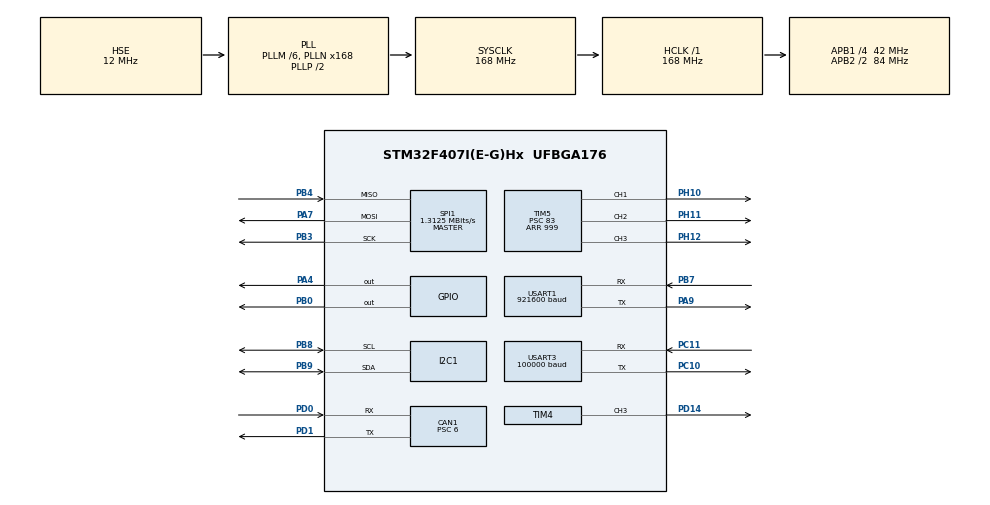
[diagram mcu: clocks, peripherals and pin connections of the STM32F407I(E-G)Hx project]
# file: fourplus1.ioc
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CAN1.BS1=CAN_BS1_3TQ
CAN1.BS2=CAN_BS2_3TQ
CAN1.CalculateBaudRate=1000000
CAN1.CalculateTimeBit=1000
CAN1.CalculateTimeQuantum=142.85714285714286
CAN1.Prescaler=6
Dma.Request0=USART3_RX
Dma.Request1=USART1_TX
Dma.USART1_TX.1.Direction=DMA_MEMORY_TO_PERIPH
Dma.USART1_TX.1.FIFOMode=DMA_FIFOMODE_DISABLE
Dma.USART1_TX.1.Instance=DMA2_Stream7
Dma.USART1_TX.1.MemDataAlignment=DMA_MDATAALIGN_BYTE
Dma.USART1_TX.1.MemInc=DMA_MINC_ENABLE
Dma.USART1_TX.1.Mode=DMA_NORMAL
Dma.USART1_TX.1.PeriphDataAlignment=DMA_PDATAALIGN_BYTE
Dma.USART1_TX.1.PeriphInc=DMA_PINC_DISABLE
Dma.USART1_TX.1.Priority=DMA_PRIORITY_LOW
Dma.USART3_RX.0.Direction=DMA_PERIPH_TO_MEMORY
Dma.USART3_RX.0.FIFOMode=DMA_FIFOMODE_DISABLE
Dma.USART3_RX.0.Instance=DMA1_Stream1
Dma.USART3_RX.0.MemDataAlignment=DMA_MDATAALIGN_BYTE
Dma.USART3_RX.0.MemInc=DMA_MINC_ENABLE
Dma.USART3_RX.0.Mode=DMA_NORMAL
Dma.USART3_RX.0.PeriphDataAlignment=DMA_PDATAALIGN_BYTE
Dma.USART3_RX.0.PeriphInc=DMA_PINC_DISABLE
Dma.USART3_RX.0.Priority=DMA_PRIORITY_LOW
FREERTOS.Tasks01=defaultTask,24,128,StartDefaultTask,Default,NULL,Dynamic,NULL,NULL;buzzer_task,8,128,StartBuzzerTask,Default,NULL,Dynamic,NULL,NULL;led_task,8,128,StartLedTask,Default,NULL,Dynamic,NULL,NULL;imu_task,40,256,StartImuTask,Default,NULL,Dynamic,NULL,NULL;rc_task,24,256,StartRcTask,Default,NULL,Dynamic,NULL,NULL;motor_task,48,256,StartMotorTask,Default,NULL,Dynamic,NULL,NULL
FREERTOS.configUSE_NEWLIB_REENTRANT=1
I2C1.I2C_Mode=I2C_Fast
Mcu.Family=STM32F4
Mcu.Name=STM32F407I(E-G)Hx
Mcu.Package=UFBGA176
NVIC.CAN1_RX0_IRQn=true\:5\:0\:false\:false\:true\:true\:true\:true\:true
NVIC.DMA1_Stream1_IRQn=true\:5\:0\:false\:false\:true\:true\:false\:true\:true
NVIC.DMA2_Stream7_IRQn=true\:5\:0\:false\:false\:true\:true\:false\:true\:true
NVIC.PriorityGroup=NVIC_PRIORITYGROUP_4
NVIC.TIM1_UP_TIM10_IRQn=true\:15\:0\:false\:false\:true\:false\:false\:true\:true
NVIC.TimeBase=TIM1_UP_TIM10_IRQn
NVIC.TimeBaseIP=TIM1
NVIC.USART3_IRQn=true\:5\:0\:false\:false\:true\:true\:true\:true\:true
PA13.Mode=Serial_Wire
PA13.Signal=SYS_JTMS-SWDIO
PA14.Mode=Serial_Wire
PA14.Signal=SYS_JTCK-SWCLK
PA4.PinState=GPIO_PIN_SET
PA4.Signal=GPIO_Output
PA7.Mode=Full_Duplex_Master
PA7.Signal=SPI1_MOSI
PA9.Mode=Asynchronous
PA9.Signal=USART1_TX
PB0.PinState=GPIO_PIN_SET
PB0.Signal=GPIO_Output
PB3.Mode=Full_Duplex_Master
PB3.Signal=SPI1_SCK
PB4.Mode=Full_Duplex_Master
PB4.Signal=SPI1_MISO
PB7.Mode=Asynchronous
PB7.Signal=USART1_RX
PB8.Mode=I2C
PB8.Signal=I2C1_SCL
PB9.Mode=I2C
PB9.Signal=I2C1_SDA
PC10.Mode=Asynchronous
PC10.Signal=USART3_TX
PC11.Mode=Asynchronous
PC11.Signal=USART3_RX
PD0.Mode=CAN_Activate
PD0.Signal=CAN1_RX
PD1.Mode=CAN_Activate
PD1.Signal=CAN1_TX
PD14.Signal=S_TIM4_CH3
PH0-OSC_IN.Mode=HSE-External-Oscillator
PH0-OSC_IN.Signal=RCC_OSC_IN
PH1-OSC_OUT.Mode=HSE-External-Oscillator
PH1-OSC_OUT.Signal=RCC_OSC_OUT
PH10.Signal=S_TIM5_CH1
PH11.Signal=S_TIM5_CH2
PH12.Signal=S_TIM5_CH3
ProjectManager.HeapSize=0x200
ProjectManager.StackSize=0x400
ProjectManager.TargetToolchain=CMake
RCC.48MHZClocksFreq_Value=84000000
RCC.AHBFreq_Value=168000000
RCC.APB1CLKDivider=RCC_HCLK_DIV4
RCC.APB1Freq_Value=42000000
RCC.APB1TimFreq_Value=84000000
RCC.APB2CLKDivider=RCC_HCLK_DIV2
RCC.APB2Freq_Value=84000000
RCC.APB2TimFreq_Value=168000000
RCC.CortexFreq_Value=168000000
RCC.HCLKFreq_Value=168000000
RCC.HSE_VALUE=12000000
RCC.HSI_VALUE=16000000
RCC.LSE_VALUE=32768
RCC.PLLM=6
RCC.PLLN=168
RCC.PLLSourceVirtual=RCC_PLLSOURCE_HSE
RCC.SYSCLKFreq_VALUE=168000000
RCC.SYSCLKSource=RCC_SYSCLKSOURCE_PLLCLK
RCC.VCOOutputFreq_Value=336000000
SH.S_TIM4_CH3.0=TIM4_CH3,PWM Generation3 CH3
SH.S_TIM5_CH1.0=TIM5_CH1,PWM Generation1 CH1
SH.S_TIM5_CH2.0=TIM5_CH2,PWM Generation2 CH2
SH.S_TIM5_CH3.0=TIM5_CH3,PWM Generation3 CH3
SPI1.BaudRatePrescaler=SPI_BAUDRATEPRESCALER_64
SPI1.CLKPhase=SPI_PHASE_2EDGE
SPI1.CLKPolarity=SPI_POLARITY_HIGH
SPI1.CalculateBaudRate=1.3125 MBits/s
SPI1.Direction=SPI_DIRECTION_2LINES
SPI1.Mode=SPI_MODE_MASTER
SPI1.VirtualType=VM_MASTER
TIM4.Channel-PWM\ Generation3\ CH3=TIM_CHANNEL_3
TIM4.Period=999
TIM4.Prescaler=83
TIM4.Pulse-PWM\ Generation3\ CH3=500
TIM5.Channel-PWM\ Generation1\ CH1=TIM_CHANNEL_1
TIM5.Channel-PWM\ Generation2\ CH2=TIM_CHANNEL_2
TIM5.Channel-PWM\ Generation3\ CH3=TIM_CHANNEL_3
TIM5.Period=999
TIM5.Prescaler=83
USART1.BaudRate=921600
USART1.VirtualMode=VM_ASYNC
USART3.BaudRate=100000
USART3.Parity=PARITY_EVEN
USART3.VirtualMode=VM_ASYNC
USART3.WordLength=WORDLENGTH_9B
VP_FREERTOS_VS_CMSIS_V2.Mode=CMSIS_V2
VP_SYS_VS_tim1.Mode=TIM1
VP_TIM4_VS_ClockSourceINT.Mode=Internal
VP_TIM5_VS_ClockSourceINT.Mode=Internal
board=custom

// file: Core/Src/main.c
/* USER CODE BEGIN Header */
/**
  ******************************************************************************
  * @file           : main.c
  * @brief          : Main program body
  ******************************************************************************
  * @attention
  *
  * Copyright (c) 2026 STMicroelectronics.
  * All rights reserved.
  *
  * This software is licensed under terms that can be found in the LICENSE file
  * in the root directory of this software component.
  * If no LICENSE file comes with this software, it is provided AS-IS.
  *
  ******************************************************************************
  */
/* USER CODE END Header */
#include "main.h"
#include "cmsis_os.h"
#include "can.h"
#include "dma.h"
#include "i2c.h"
#include "spi.h"
#include "tim.h"
#include "usart.h"
#include "gpio.h"

void SystemClock_Config(void);
void MX_FREERTOS_Init(void);

int main(void)
{

  /* MCU Configuration--------------------------------------------------------*/

  /* Reset of all peripherals, Initializes the Flash interface and the Systick. */
  HAL_Init();

  /* Configure the system clock */
  SystemClock_Config();

  /* Initialize all configured peripherals */
  MX_GPIO_Init();
  MX_DMA_Init();
  MX_USART1_UART_Init();
  MX_USART3_UART_Init();
  MX_CAN1_Init();
  MX_I2C1_Init();
  MX_SPI1_Init();
  MX_TIM4_Init();
  MX_TIM5_Init();

  /* Init scheduler */
  osKernelInitialize();  /* Call init function for freertos objects (in cmsis_os2.c) */
  MX_FREERTOS_Init();

  /* Start scheduler */
  osKernelStart();

  /* We should never get here as control is now taken by the scheduler */

  /* Infinite loop */
  while (1)
  {

  }
}

void SystemClock_Config(void)
{
  RCC_OscInitTypeDef RCC_OscInitStruct = {0};
  RCC_ClkInitTypeDef RCC_ClkInitStruct = {0};

  /** Configure the main internal regulator output voltage
  */
  __HAL_RCC_PWR_CLK_ENABLE();
  __HAL_PWR_VOLTAGESCALING_CONFIG(PWR_REGULATOR_VOLTAGE_SCALE1);

  /** Initializes the RCC Oscillators according to the specified parameters
  * in the RCC_OscInitTypeDef structure.
  */
  RCC_OscInitStruct.OscillatorType = RCC_OSCILLATORTYPE_HSE;
  RCC_OscInitStruct.HSEState = RCC_HSE_ON;
  RCC_OscInitStruct.PLL.PLLState = RCC_PLL_ON;
  RCC_OscInitStruct.PLL.PLLSource = RCC_PLLSOURCE_HSE;
  RCC_OscInitStruct.PLL.PLLM = 6;
  RCC_OscInitStruct.PLL.PLLN = 168;
  RCC_OscInitStruct.PLL.PLLP = RCC_PLLP_DIV2;
  RCC_OscInitStruct.PLL.PLLQ = 4;
  if (HAL_RCC_OscConfig(&RCC_OscInitStruct) != HAL_OK)
  {
    Error_Handler();
  }

  /** Initializes the CPU, AHB and APB buses clocks
  */
  RCC_ClkInitStruct.ClockType = RCC_CLOCKTYPE_HCLK|RCC_CLOCKTYPE_SYSCLK
                              |RCC_CLOCKTYPE_PCLK1|RCC_CLOCKTYPE_PCLK2;
  RCC_ClkInitStruct.SYSCLKSource = RCC_SYSCLKSOURCE_PLLCLK;
  RCC_ClkInitStruct.AHBCLKDivider = RCC_SYSCLK_DIV1;
  RCC_ClkInitStruct.APB1CLKDivider = RCC_HCLK_DIV4;
  RCC_ClkInitStruct.APB2CLKDivider = RCC_HCLK_DIV2;

  if (HAL_RCC_ClockConfig(&RCC_ClkInitStruct, FLASH_LATENCY_5) != HAL_OK)
  {
    Error_Handler();
  }
}

/* USER CODE BEGIN 4 */
#include <stdio.h>

int __io_putchar(int ch)
{
    HAL_UART_Transmit(&huart1, (uint8_t *)&ch, 1, 0xFFFF);
    return ch;
}
/* USER CODE END 4 */

void HAL_TIM_PeriodElapsedCallback(TIM_HandleTypeDef *htim)
{
  if (htim->Instance == TIM1)
  {
    HAL_IncTick();
  }
}

void Error_Handler(void)
{
  __disable_irq();
  while (1)
  {
  }
}

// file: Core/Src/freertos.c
/* USER CODE BEGIN Header */
/**
  ******************************************************************************
  * File Name          : freertos.c
  * Description        : Code for freertos applications
  ******************************************************************************
  * @attention
  *
  * Copyright (c) 2026 STMicroelectronics.
  * All rights reserved.
  *
  * This software is licensed under terms that can be found in the LICENSE file
  * in the root directory of this software component.
  * If no LICENSE file comes with this software, it is provided AS-IS.
  *
  ******************************************************************************
  */
/* USER CODE END Header */

#include "FreeRTOS.h"
#include "task.h"
#include "main.h"
#include "cmsis_os.h"

/* Definitions for defaultTask */
osThreadId_t defaultTaskHandle;
const osThreadAttr_t defaultTask_attributes = {
  .name = "defaultTask",
  .stack_size = 128 * 4,
  .priority = (osPriority_t) osPriorityNormal,
};
/* Definitions for buzzer_task */
osThreadId_t buzzer_taskHandle;
const osThreadAttr_t buzzer_task_attributes = {
  .name = "buzzer_task",
  .stack_size = 128 * 4,
  .priority = (osPriority_t) osPriorityLow,
};
/* Definitions for led_task */
osThreadId_t led_taskHandle;
const osThreadAttr_t led_task_attributes = {
  .name = "led_task",
  .stack_size = 128 * 4,
  .priority = (osPriority_t) osPriorityLow,
};
/* Definitions for imu_task */
osThreadId_t imu_taskHandle;
const osThreadAttr_t imu_task_attributes = {
  .name = "imu_task",
  .stack_size = 256 * 4,
  .priority = (osPriority_t) osPriorityHigh,
};
/* Definitions for rc_task */
osThreadId_t rc_taskHandle;
const osThreadAttr_t rc_task_attributes = {
  .name = "rc_task",
  .stack_size = 256 * 4,
  .priority = (osPriority_t) osPriorityNormal,
};
/* Definitions for motor_task */
osThreadId_t motor_taskHandle;
const osThreadAttr_t motor_task_attributes = {
  .name = "motor_task",
  .stack_size = 256 * 4,
  .priority = (osPriority_t) osPriorityRealtime,
};

void StartDefaultTask(void *argument);
void StartBuzzerTask(void *argument);
void StartLedTask(void *argument);
void StartImuTask(void *argument);
void StartRcTask(void *argument);
void StartMotorTask(void *argument);

void MX_FREERTOS_Init(void); /* (MISRA C 2004 rule 8.1) */

void MX_FREERTOS_Init(void) {

  /* Create the thread(s) */
  /* creation of defaultTask */
  defaultTaskHandle = osThreadNew(StartDefaultTask, NULL, &defaultTask_attributes);

  /* creation of buzzer_task */
  buzzer_taskHandle = osThreadNew(StartBuzzerTask, NULL, &buzzer_task_attributes);

  /* creation of led_task */
  led_taskHandle = osThreadNew(StartLedTask, NULL, &led_task_attributes);

  /* creation of imu_task */
  imu_taskHandle = osThreadNew(StartImuTask, NULL, &imu_task_attributes);

  /* creation of rc_task */
  rc_taskHandle = osThreadNew(StartRcTask, NULL, &rc_task_attributes);

  /* creation of motor_task */
  motor_taskHandle = osThreadNew(StartMotorTask, NULL, &motor_task_attributes);

}

void StartDefaultTask(void *argument)
{
  for(;;)
  {
    osDelay(1);
  }
}

void StartBuzzerTask(void *argument)
{
  /* USER CODE BEGIN StartBuzzerTask */
  extern void buzzer_task(void);
  buzzer_task();
  /* USER CODE END StartBuzzerTask */
}

void StartLedTask(void *argument)
{
  /* USER CODE BEGIN StartLedTask */
  /* Infinite loop */
  extern void led_task();
  led_task();
  /* USER CODE END StartLedTask */
}

void StartImuTask(void *argument)
{
  /* USER CODE BEGIN StartImuTask */
  extern void imu_task(void);
  imu_task();
  /* USER CODE END StartImuTask */
}

void StartRcTask(void *argument)
{
  /* USER CODE BEGIN StartRcTask */
  extern void uart_task(void);
  uart_task();
  /* USER CODE END StartRcTask */
}

void StartMotorTask(void *argument)
{
  /* USER CODE BEGIN StartMotorTask */
  extern void can_task(void);
  can_task();
  /* USER CODE END StartMotorTask */
}
